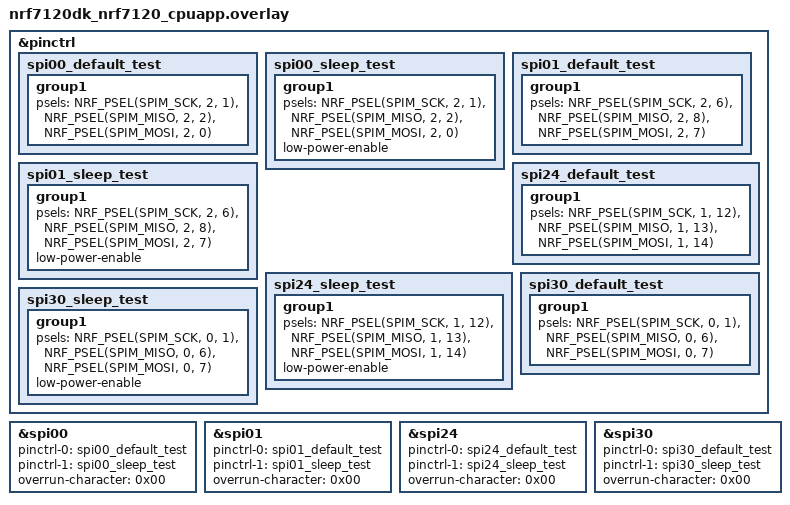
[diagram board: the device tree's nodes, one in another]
&pinctrl {
	spi00_default_test: spi00_default_test {
		group1 {
			psels = <NRF_PSEL(SPIM_SCK, 2, 1)>,
				<NRF_PSEL(SPIM_MISO, 2, 2)>,
				<NRF_PSEL(SPIM_MOSI, 2, 0)>;
		};
	};

	spi00_sleep_test: spi00_sleep_test {
		group1 {
			psels = <NRF_PSEL(SPIM_SCK, 2, 1)>,
				<NRF_PSEL(SPIM_MISO, 2, 2)>,
				<NRF_PSEL(SPIM_MOSI, 2, 0)>;
			low-power-enable;
		};
	};

	spi01_default_test: spi01_default_test {
		group1 {
			psels = <NRF_PSEL(SPIM_SCK, 2, 6)>,
				<NRF_PSEL(SPIM_MISO, 2, 8)>,
				<NRF_PSEL(SPIM_MOSI, 2, 7)>;
		};
	};

	spi01_sleep_test: spi01_sleep_test {
		group1 {
			psels = <NRF_PSEL(SPIM_SCK, 2, 6)>,
				<NRF_PSEL(SPIM_MISO, 2, 8)>,
				<NRF_PSEL(SPIM_MOSI, 2, 7)>;
			low-power-enable;
		};
	};

	spi24_default_test: spi24_default_test {
		group1 {
			psels = <NRF_PSEL(SPIM_SCK, 1, 12)>,
				<NRF_PSEL(SPIM_MISO, 1, 13)>,
				<NRF_PSEL(SPIM_MOSI, 1, 14)>;
		};
	};

	spi24_sleep_test: spi24_sleep_test {
		group1 {
			psels = <NRF_PSEL(SPIM_SCK, 1, 12)>,
				<NRF_PSEL(SPIM_MISO, 1, 13)>,
				<NRF_PSEL(SPIM_MOSI, 1, 14)>;
			low-power-enable;
		};
	};

	spi30_default_test: spi30_default_test {
		group1 {
			psels = <NRF_PSEL(SPIM_SCK, 0, 1)>,
				<NRF_PSEL(SPIM_MISO, 0, 6)>,
				<NRF_PSEL(SPIM_MOSI, 0, 7)>;
		};
	};

	spi30_sleep_test: spi30_sleep_test {
		group1 {
			psels = <NRF_PSEL(SPIM_SCK, 0, 1)>,
				<NRF_PSEL(SPIM_MISO, 0, 6)>,
				<NRF_PSEL(SPIM_MOSI, 0, 7)>;
			low-power-enable;
		};
	};
};

&spi00 {
	status = "okay";
	pinctrl-0 = <&spi00_default_test>;
	pinctrl-1 = <&spi00_sleep_test>;
	pinctrl-names = "default", "sleep";
	overrun-character = <0x00>;
};

&spi01 {
	status = "okay";
	pinctrl-0 = <&spi01_default_test>;
	pinctrl-1 = <&spi01_sleep_test>;
	pinctrl-names = "default", "sleep";
	overrun-character = <0x00>;
};

&spi24 {
	status = "okay";
	pinctrl-0 = <&spi24_default_test>;
	pinctrl-1 = <&spi24_sleep_test>;
	pinctrl-names = "default", "sleep";
	overrun-character = <0x00>;
};

&spi30 {
	status = "okay";
	pinctrl-0 = <&spi30_default_test>;
	pinctrl-1 = <&spi30_sleep_test>;
	pinctrl-names = "default", "sleep";
	overrun-character = <0x00>;
};
